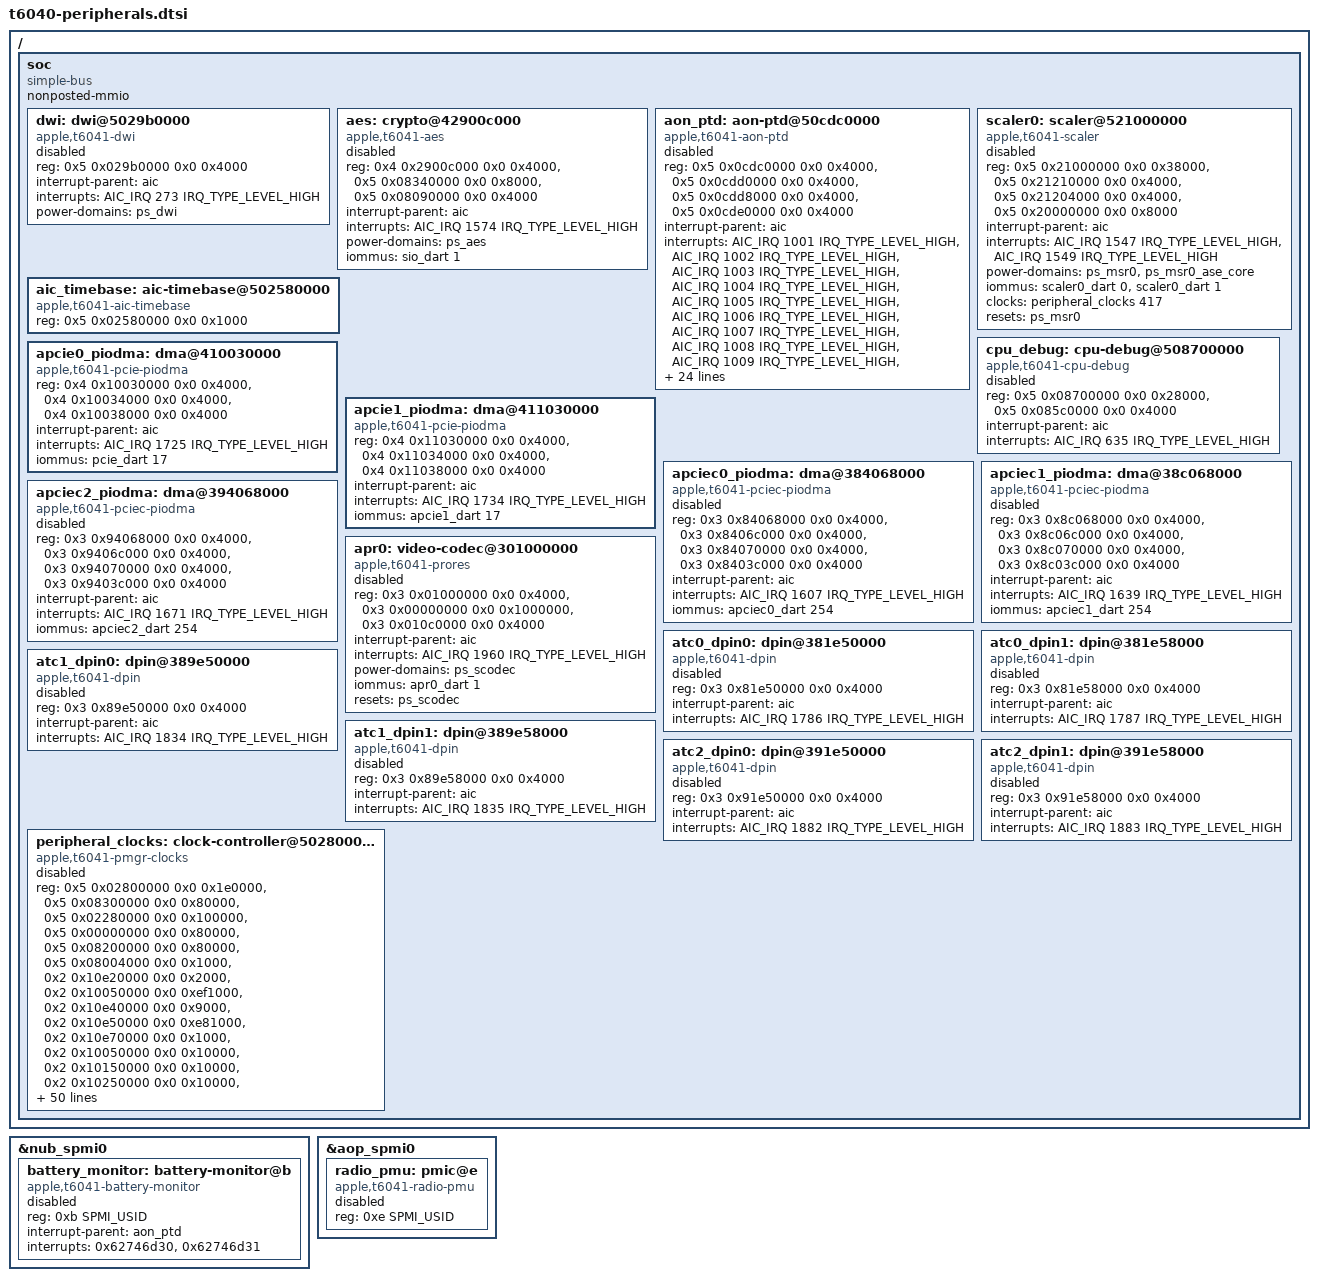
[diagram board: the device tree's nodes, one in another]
// SPDX-License-Identifier: GPL-2.0-only OR MIT
/*
 * Structural hardware resources from the board's saved Apple Device Tree.
 * Keep unqualified blocks disabled: describing them does not transfer
 * ownership from firmware or make their registers safe to access.
 */

/ {
	soc: soc {
		compatible = "simple-bus";
		#address-cells = <2>;
		#size-cells = <2>;
		ranges;
		nonposted-mmio;
	};
};

&soc {
	/* ADT /arm-io/dwi. */
	dwi: dwi@5029b0000 {
		compatible = "apple,t6041-dwi", "apple,dwi";
		reg = <0x5 0x029b0000 0x0 0x4000>;
		interrupt-parent = <&aic>;
		interrupts = <AIC_IRQ 273 IRQ_TYPE_LEVEL_HIGH>;
		power-domains = <&ps_dwi>;
		status = "disabled";
	};

	/* ADT /arm-io/aes. */
	aes: crypto@42900c000 {
		compatible = "apple,t6041-aes", "apple,aes";
		reg = <0x4 0x2900c000 0x0 0x4000>,
		      <0x5 0x08340000 0x0 0x8000>,
		      <0x5 0x08090000 0x0 0x4000>;
		interrupt-parent = <&aic>;
		interrupts = <AIC_IRQ 1574 IRQ_TYPE_LEVEL_HIGH>;
		power-domains = <&ps_aes>;
		iommus = <&sio_dart 1>;
		status = "disabled";
	};

	/* ADT /arm-io/aon-ptd. */
	aon_ptd: aon-ptd@50cdc0000 {
		compatible = "apple,t6041-aon-ptd", "apple,aon-ptd";
		reg = <0x5 0x0cdc0000 0x0 0x4000>,
		      <0x5 0x0cdd0000 0x0 0x4000>,
		      <0x5 0x0cdd8000 0x0 0x4000>,
		      <0x5 0x0cde0000 0x0 0x4000>;
		interrupt-parent = <&aic>;
		interrupts = <AIC_IRQ 1001 IRQ_TYPE_LEVEL_HIGH>,
		             <AIC_IRQ 1002 IRQ_TYPE_LEVEL_HIGH>,
		             <AIC_IRQ 1003 IRQ_TYPE_LEVEL_HIGH>,
		             <AIC_IRQ 1004 IRQ_TYPE_LEVEL_HIGH>,
		             <AIC_IRQ 1005 IRQ_TYPE_LEVEL_HIGH>,
		             <AIC_IRQ 1006 IRQ_TYPE_LEVEL_HIGH>,
		             <AIC_IRQ 1007 IRQ_TYPE_LEVEL_HIGH>,
		             <AIC_IRQ 1008 IRQ_TYPE_LEVEL_HIGH>,
		             <AIC_IRQ 1009 IRQ_TYPE_LEVEL_HIGH>,
		             <AIC_IRQ 1010 IRQ_TYPE_LEVEL_HIGH>,
		             <AIC_IRQ 1011 IRQ_TYPE_LEVEL_HIGH>,
		             <AIC_IRQ 1012 IRQ_TYPE_LEVEL_HIGH>,
		             <AIC_IRQ 1013 IRQ_TYPE_LEVEL_HIGH>,
		             <AIC_IRQ 1014 IRQ_TYPE_LEVEL_HIGH>,
		             <AIC_IRQ 1015 IRQ_TYPE_LEVEL_HIGH>,
		             <AIC_IRQ 1016 IRQ_TYPE_LEVEL_HIGH>,
		             <AIC_IRQ 1017 IRQ_TYPE_LEVEL_HIGH>,
		             <AIC_IRQ 1018 IRQ_TYPE_LEVEL_HIGH>,
		             <AIC_IRQ 1019 IRQ_TYPE_LEVEL_HIGH>,
		             <AIC_IRQ 1020 IRQ_TYPE_LEVEL_HIGH>,
		             <AIC_IRQ 1021 IRQ_TYPE_LEVEL_HIGH>,
		             <AIC_IRQ 1022 IRQ_TYPE_LEVEL_HIGH>,
		             <AIC_IRQ 1023 IRQ_TYPE_LEVEL_HIGH>,
		             <AIC_IRQ 1024 IRQ_TYPE_LEVEL_HIGH>,
		             <AIC_IRQ 1025 IRQ_TYPE_LEVEL_HIGH>,
		             <AIC_IRQ 1026 IRQ_TYPE_LEVEL_HIGH>,
		             <AIC_IRQ 1027 IRQ_TYPE_LEVEL_HIGH>,
		             <AIC_IRQ 1028 IRQ_TYPE_LEVEL_HIGH>,
		             <AIC_IRQ 1029 IRQ_TYPE_LEVEL_HIGH>,
		             <AIC_IRQ 1030 IRQ_TYPE_LEVEL_HIGH>,
		             <AIC_IRQ 1031 IRQ_TYPE_LEVEL_HIGH>,
		             <AIC_IRQ 1032 IRQ_TYPE_LEVEL_HIGH>;
		status = "disabled";
	};

	/* ADT /arm-io/scaler0. */
	scaler0: scaler@521000000 {
		compatible = "apple,t6041-scaler", "apple,scaler";
		reg = <0x5 0x21000000 0x0 0x38000>,
		      <0x5 0x21210000 0x0 0x4000>,
		      <0x5 0x21204000 0x0 0x4000>,
		      <0x5 0x20000000 0x0 0x8000>;
		interrupt-parent = <&aic>;
		interrupts = <AIC_IRQ 1547 IRQ_TYPE_LEVEL_HIGH>,
		             <AIC_IRQ 1549 IRQ_TYPE_LEVEL_HIGH>;
		power-domains = <&ps_msr0>,
		                <&ps_msr0_ase_core>;
		iommus = <&scaler0_dart 0>,
		         <&scaler0_dart 1>;
		clocks = <&peripheral_clocks 417>;
		resets = <&ps_msr0>;
		status = "disabled";
	};

	/* ADT /arm-io/aic-timebase. */
	aic_timebase: aic-timebase@502580000 {
		compatible = "apple,t6041-aic-timebase", "apple,aic-timebase";
		reg = <0x5 0x02580000 0x0 0x1000>;
	};

	/* ADT /arm-io/dbgCPU. */
	cpu_debug: cpu-debug@508700000 {
		compatible = "apple,t6041-cpu-debug", "apple,cpu-debug";
		reg = <0x5 0x08700000 0x0 0x28000>,
		      <0x5 0x085c0000 0x0 0x4000>;
		interrupt-parent = <&aic>;
		interrupts = <AIC_IRQ 635 IRQ_TYPE_LEVEL_HIGH>;
		status = "disabled";
	};

	/* ADT /arm-io/apcie0-piodma. */
	apcie0_piodma: dma@410030000 {
		compatible = "apple,t6041-pcie-piodma", "apple,pcie-piodma";
		reg = <0x4 0x10030000 0x0 0x4000>,
		      <0x4 0x10034000 0x0 0x4000>,
		      <0x4 0x10038000 0x0 0x4000>;
		interrupt-parent = <&aic>;
		interrupts = <AIC_IRQ 1725 IRQ_TYPE_LEVEL_HIGH>;
		iommus = <&pcie_dart 17>;
		status = "okay";
	};

	/* ADT /arm-io/apcie1-piodma. */
	apcie1_piodma: dma@411030000 {
		compatible = "apple,t6041-pcie-piodma", "apple,pcie-piodma";
		reg = <0x4 0x11030000 0x0 0x4000>,
		      <0x4 0x11034000 0x0 0x4000>,
		      <0x4 0x11038000 0x0 0x4000>;
		interrupt-parent = <&aic>;
		interrupts = <AIC_IRQ 1734 IRQ_TYPE_LEVEL_HIGH>;
		iommus = <&apcie1_dart 17>;
		status = "okay";
	};

	/* ADT /arm-io/apciec0-piodma. */
	apciec0_piodma: dma@384068000 {
		compatible = "apple,t6041-pciec-piodma", "apple,pciec-piodma";
		reg = <0x3 0x84068000 0x0 0x4000>,
		      <0x3 0x8406c000 0x0 0x4000>,
		      <0x3 0x84070000 0x0 0x4000>,
		      <0x3 0x8403c000 0x0 0x4000>;
		interrupt-parent = <&aic>;
		interrupts = <AIC_IRQ 1607 IRQ_TYPE_LEVEL_HIGH>;
		iommus = <&apciec0_dart 254>;
		status = "disabled";
	};

	/* ADT /arm-io/apciec1-piodma. */
	apciec1_piodma: dma@38c068000 {
		compatible = "apple,t6041-pciec-piodma", "apple,pciec-piodma";
		reg = <0x3 0x8c068000 0x0 0x4000>,
		      <0x3 0x8c06c000 0x0 0x4000>,
		      <0x3 0x8c070000 0x0 0x4000>,
		      <0x3 0x8c03c000 0x0 0x4000>;
		interrupt-parent = <&aic>;
		interrupts = <AIC_IRQ 1639 IRQ_TYPE_LEVEL_HIGH>;
		iommus = <&apciec1_dart 254>;
		status = "disabled";
	};

	/* ADT /arm-io/apciec2-piodma. */
	apciec2_piodma: dma@394068000 {
		compatible = "apple,t6041-pciec-piodma", "apple,pciec-piodma";
		reg = <0x3 0x94068000 0x0 0x4000>,
		      <0x3 0x9406c000 0x0 0x4000>,
		      <0x3 0x94070000 0x0 0x4000>,
		      <0x3 0x9403c000 0x0 0x4000>;
		interrupt-parent = <&aic>;
		interrupts = <AIC_IRQ 1671 IRQ_TYPE_LEVEL_HIGH>;
		iommus = <&apciec2_dart 254>;
		status = "disabled";
	};

	/* ADT /arm-io/apr0. */
	apr0: video-codec@301000000 {
		compatible = "apple,t6041-prores", "apple,prores";
		reg = <0x3 0x01000000 0x0 0x4000>,
		      <0x3 0x00000000 0x0 0x1000000>,
		      <0x3 0x010c0000 0x0 0x4000>;
		reg-names = "core", "wrapper", "aux";
		interrupt-parent = <&aic>;
		interrupts = <AIC_IRQ 1960 IRQ_TYPE_LEVEL_HIGH>;
		power-domains = <&ps_scodec>;
		iommus = <&apr0_dart 1>;
		resets = <&ps_scodec>;
		status = "disabled";
	};

	/* ADT /arm-io/atc0-dpin0. */
	atc0_dpin0: dpin@381e50000 {
		compatible = "apple,t6041-dpin", "apple,dpin";
		reg = <0x3 0x81e50000 0x0 0x4000>;
		interrupt-parent = <&aic>;
		interrupts = <AIC_IRQ 1786 IRQ_TYPE_LEVEL_HIGH>;
		status = "disabled";
	};

	/* ADT /arm-io/atc0-dpin1. */
	atc0_dpin1: dpin@381e58000 {
		compatible = "apple,t6041-dpin", "apple,dpin";
		reg = <0x3 0x81e58000 0x0 0x4000>;
		interrupt-parent = <&aic>;
		interrupts = <AIC_IRQ 1787 IRQ_TYPE_LEVEL_HIGH>;
		status = "disabled";
	};

	/* ADT /arm-io/atc1-dpin0. */
	atc1_dpin0: dpin@389e50000 {
		compatible = "apple,t6041-dpin", "apple,dpin";
		reg = <0x3 0x89e50000 0x0 0x4000>;
		interrupt-parent = <&aic>;
		interrupts = <AIC_IRQ 1834 IRQ_TYPE_LEVEL_HIGH>;
		status = "disabled";
	};

	/* ADT /arm-io/atc1-dpin1. */
	atc1_dpin1: dpin@389e58000 {
		compatible = "apple,t6041-dpin", "apple,dpin";
		reg = <0x3 0x89e58000 0x0 0x4000>;
		interrupt-parent = <&aic>;
		interrupts = <AIC_IRQ 1835 IRQ_TYPE_LEVEL_HIGH>;
		status = "disabled";
	};

	/* ADT /arm-io/atc2-dpin0. */
	atc2_dpin0: dpin@391e50000 {
		compatible = "apple,t6041-dpin", "apple,dpin";
		reg = <0x3 0x91e50000 0x0 0x4000>;
		interrupt-parent = <&aic>;
		interrupts = <AIC_IRQ 1882 IRQ_TYPE_LEVEL_HIGH>;
		status = "disabled";
	};

	/* ADT /arm-io/atc2-dpin1. */
	atc2_dpin1: dpin@391e58000 {
		compatible = "apple,t6041-dpin", "apple,dpin";
		reg = <0x3 0x91e58000 0x0 0x4000>;
		interrupt-parent = <&aic>;
		interrupts = <AIC_IRQ 1883 IRQ_TYPE_LEVEL_HIGH>;
		status = "disabled";
	};




	/* Clock IDs are SoC hardware selectors, not ADT phandles. */
	peripheral_clocks: clock-controller@502800000 {
		compatible = "apple,t6041-pmgr-clocks", "apple,pmgr-clocks";
		/* ADT /arm-io/pmgr register banks, in hardware-description order. */
		reg = <0x5 0x02800000 0x0 0x1e0000>,
		      <0x5 0x08300000 0x0 0x80000>,
		      <0x5 0x02280000 0x0 0x100000>,
		      <0x5 0x00000000 0x0 0x80000>,
		      <0x5 0x08200000 0x0 0x80000>,
		      <0x5 0x08004000 0x0 0x1000>,
		      <0x2 0x10e20000 0x0 0x2000>,
		      <0x2 0x10050000 0x0 0xef1000>,
		      <0x2 0x10e40000 0x0 0x9000>,
		      <0x2 0x10e50000 0x0 0xe81000>,
		      <0x2 0x10e70000 0x0 0x1000>,
		      <0x2 0x10050000 0x0 0x10000>,
		      <0x2 0x10150000 0x0 0x10000>,
		      <0x2 0x10250000 0x0 0x10000>,
		      <0x2 0x10350000 0x0 0x10000>,
		      <0x2 0x11e20000 0x0 0x2000>,
		      <0x2 0x11050000 0x0 0xef1000>,
		      <0x2 0x11e40000 0x0 0xb000>,
		      <0x2 0x11e50000 0x0 0xe81000>,
		      <0x2 0x11e70000 0x0 0x1000>,
		      <0x2 0x11050000 0x0 0x10000>,
		      <0x2 0x11150000 0x0 0x10000>,
		      <0x2 0x11250000 0x0 0x10000>,
		      <0x2 0x11350000 0x0 0x10000>,
		      <0x2 0x11450000 0x0 0x10000>,
		      <0x2 0x11550000 0x0 0x10000>,
		      <0x2 0x12e20000 0x0 0x2000>,
		      <0x2 0x12050000 0x0 0xef1000>,
		      <0x2 0x12e40000 0x0 0xb000>,
		      <0x2 0x12e50000 0x0 0xe81000>,
		      <0x2 0x12e70000 0x0 0x1000>,
		      <0x2 0x12050000 0x0 0x10000>,
		      <0x2 0x12150000 0x0 0x10000>,
		      <0x2 0x12250000 0x0 0x10000>,
		      <0x2 0x12350000 0x0 0x10000>,
		      <0x2 0x12450000 0x0 0x10000>,
		      <0x2 0x12550000 0x0 0x10000>,
		      <0x5 0x02800000 0x0 0x18000>,
		      <0x5 0x0282c000 0x0 0x4000>,
		      <0x5 0x02850000 0x0 0x4000>,
		      <0x5 0x02880000 0x0 0x1c000>,
		      <0x5 0x02900000 0x0 0x24000>,
		      <0x5 0x028f0000 0x0 0x4000>,
		      <0x5 0x028e0000 0x0 0x4000>,
		      <0x5 0x02820000 0x0 0x4000>,
		      <0x5 0x08330000 0x0 0x10000>,
		      <0x5 0x08374000 0x0 0x4000>,
		      <0x5 0x08360000 0x0 0x4000>,
		      <0x5 0x00200000 0x0 0x8000>,
		      <0x5 0x00400000 0x0 0x34000>,
		      <0x5 0x003c0000 0x0 0x30000>,
		      <0x5 0x08800000 0x0 0xa8000>,
		      <0x4 0x85878000 0x0 0x4000>,
		      <0x2 0x88eb0000 0x0 0x4000>,
		      <0x2 0x88e80000 0x0 0x30000>,
		      <0x5 0x08900000 0x0 0x18000>,
		      <0x5 0x00210000 0x0 0x8000>,
		      <0x5 0x0020c000 0x0 0x4000>,
		      <0x5 0x08004000 0x0 0x1000>,
		      <0x5 0x0007a000 0x0 0x4000>,
		      <0x5 0x04000000 0x0 0x1000000>,
		      <0x2 0x88e1c000 0x0 0x4000>,
		      <0x5 0x022a0000 0x0 0x4000>;
		#clock-cells = <1>;
		apple,pmgr = <&pmgr>;
		status = "disabled";
	};
};

&aon_ptd {
	interrupt-controller;
	#interrupt-cells = <1>;
	#address-cells = <0>;
};

&nub_spmi0 {
	battery_monitor: battery-monitor@b {
		compatible = "apple,t6041-battery-monitor", "apple,battery-monitor";
		reg = <0xb SPMI_USID>;
		interrupt-parent = <&aon_ptd>;
		interrupts = <0x62746d30>, <0x62746d31>;
		status = "disabled";
	};
};

&aop_spmi0 {
	radio_pmu: pmic@e {
		compatible = "apple,t6041-radio-pmu", "apple,radio-pmu";
		reg = <0xe SPMI_USID>;
		status = "disabled";
	};
};
